# MIK32 register map
Vendor: Mikron JSC; Series: MIK32; File version: 1.0
Registers are 32-bit, read-write, reset 0x0 unless marked. A register's access mark holds for its fields unless they carry their own. Offsets are from the block's base; [hi:lo] are bit positions.

## DAC0 — Управление ЦАП
Base 0x00085000
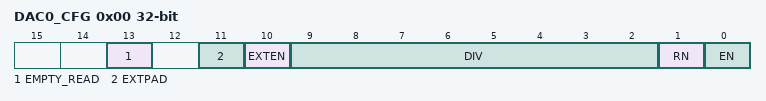
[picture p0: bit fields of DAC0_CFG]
0x00 DAC0_CFG — Регистр настройки ЦАП0
  [13] EMPTY_READ ro — Признак заполненности регистра DAC_VALUE
    0=Full (Значение, хранящееся в DAC_VALUE было сдвинуто в ЦАП, возможна запись следующего значения); 1=Empty (В регистре DAC_Value находится необработанное значение. Автоматически сбрасывается при записи в DAC_Value)
  [11] EXTPAD — Выбор источника внешнего опорного напряжения
    0=Calibrated_voltage_reference (Настраиваемый ИОН); 1=REF_DAC_PIN (Внешний вывод REF_ADC_DAC (PORT1_11))
  [10] EXTEN — Выбор источника опорного напряжения
    0=Internal (Встроенный); 1=External (Внешний)
  [9:2] DIV — Значение делителя тактового сигнала. Частота определяется как FЦАП=FIN/(DIV+1)
  [1] RN — Управление сбросом ЦАП, активный уровень «0»
  [0] EN — Управление питанием ЦАП
    0=Disable (Выключен); 1=Enable (Включен)
0x04 DAC0_VALUE — Входные данные для ЦАП0
  [11:0] VALUE — Входные данные для прерывания

## DAC1 — Управление ЦАП
Base 0x00085008
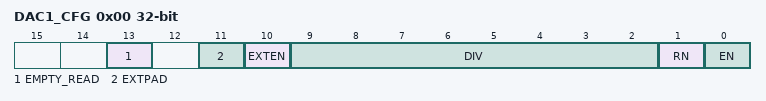
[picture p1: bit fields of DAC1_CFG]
0x00 DAC1_CFG — Регистр настройки ЦАП1
  [13] EMPTY_READ ro — Признак заполненности регистра DAC_VALUE
    0=Full (Значение, хранящееся в DAC_VALUE было сдвинуто в ЦАП, возможна запись следующего значения); 1=Empty (В регистре DAC_Value находится необработанное значение. Автоматически сбрасывается при записи в DAC_Value)
  [11] EXTPAD — Выбор источника внешнего опорного напряжения
    0=Calibrated_voltage_reference (Настраиваемый ИОН); 1=REF_DAC_PIN (Внешний вывод REF_ADC_DAC (PORT1_11))
  [10] EXTEN — Выбор источника опорного напряжения
    0=Internal (Встроенный); 1=External (Внешний)
  [9:2] DIV — Значение делителя тактового сигнала. Частота определяется как FЦАП=FIN/(DIV+1)
  [1] RN — Управление сбросом ЦАП, активный уровень «0»
  [0] EN — Управление питанием ЦАП
    0=Disable (Выключен); 1=Enable (Включен)
0x04 DAC1_VALUE — Входные данные для ЦАП1
  [11:0] VALUE — Входные данные для прерывания

## TSENS — Управление температурным сенсором
Base 0x0008501C
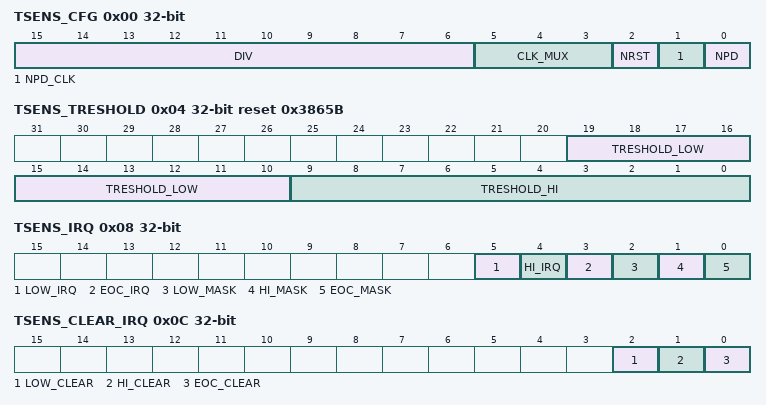
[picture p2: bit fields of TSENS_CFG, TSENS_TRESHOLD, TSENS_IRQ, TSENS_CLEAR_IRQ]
0x00 TSENS_CFG — Регистр настроек
  [15:6] DIV — Значение делителя тактового сигнала. Частота сенсора определяется как Tsens = Fin/(2*(Div + 1))
  [5:3] CLK_MUX — Выбор источника тактирования сенсора (Fin)
    0=Sys_clk (системная частота (sys_clk)); 1=HCLK (Частота шины AHB (hclk)); 2=OSC32M (Частота внешнего осциллятора 32 МГц); 3=HSI32M (Частота HSI32M); 4=OSC32K (Частота внешнего осциллятора 32 кГц); 5=LSI32K (Частота LSI32K)
  [2] NRST — Управление сбросом сенсора, активный уровень «0»
  [1] NPD_CLK — Управление тактированием сенсора
    0=Disable (Тактирование сенсора выключено); 1=Enable (Тактирование сенсора включено)
  [0] NPD — Управление питанием сенсора
    0=Disable (Сенсор выключен); 1=Enable (Сенсор включен)
0x04 TSENS_TRESHOLD reset 0x3865B — Регистр пороговых значений
  [19:10] TRESHOLD_LOW — При значении выхода сенсора менее LOW_THRESHOLD будет формироваться прерывание. Значение по умолчанию соответсвует температуре -40 *C
  [9:0] TRESHOLD_HI — При значении выхода сенсора больше HI_THRESHOLD будет формироваться прерывание. Значение по умолчанию соответсвует температуре +125 *С
0x08 TSENS_IRQ — Регистр прерываний
  [5] LOW_IRQ ro — Статус прерывания события «выход сенсора меньше порогового значения LOW_ THRESHOLD»
  [4] HI_IRQ ro — Статус прерывания события «выход сенсора больше порогового значения HI_THRESHOLD»
  [3] EOC_IRQ ro — Статус прерывания по окончанию преобразования
  [2] LOW_MASK — Маска прерывания события «выход сенсора меньше порогового значения LOW_ THRESHOLD»
  [1] HI_MASK — Маска прерывания события «выход сенсора больше порогового значения HI_THRESHOLD»
  [0] EOC_MASK — Маска прерывания по окончанию преобразования
0x0C TSENS_CLEAR_IRQ wo write-1-clears — Регистр сброса прерываний
  [2] LOW_CLEAR write-1-clears — Сброс прерывания события «выход сенсора меньше порогового значения LOW_ THRESHOLD»
  [1] HI_CLEAR write-1-clears — Сброс прерывания события «выход сенсора больше порогового значения HI_THRESHOLD»
  [0] EOC_CLEAR write-1-clears — Сброс прерывания по окончанию преобразования
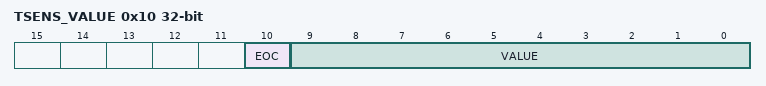
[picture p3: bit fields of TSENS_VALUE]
0x10 TSENS_VALUE ro — Регистр данных
  [10] EOC — Текущее значение выхода окончания преобразования
  [9:0] VALUE — Последнее измереннное значение сенсором
0x14 TSENS_SINGLE wo — Регистр запуска однократного измерения
  [0] SINGLE — Запуск одного измерения
0x18 TSENS_CONTINUOUS wo — Регистр запуска непрерывного измерения
  [0] CONTINUOUS — Запуск / остановка непрерывного измерения температуры

## REFV_CONFIG — Управление калибруемыми источниками напряжения и тока
Base 0x00085038
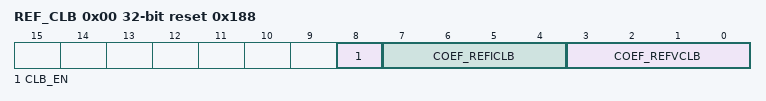
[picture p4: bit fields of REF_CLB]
0x00 REF_CLB reset 0x188 — Управление калибруемыми источниками тока и напряжения
  [8] CLB_EN — Разрешение работы калибруемых источников
    0=Disable (Включить); 1=Enable (Выключить)
  [7:4] COEF_REFICLB — Коэфициент настройки опорного источника тока
  [3:0] COEF_REFVCLB — Коэфициент настройки опорного источника напряжения

## ADC — Управление АЦП
Base 0x0008503C
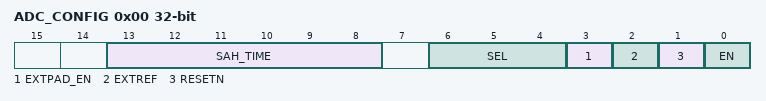
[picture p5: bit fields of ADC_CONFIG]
0x00 ADC_CONFIG — Регистр настройки АЦП
  [13:8] SAH_TIME — Время выборки очередного отсчёта в тактах АЦП
  [6:4] SEL — Выбор канала АЦП
  [3] EXTPAD_EN — Выбор источника внешнего опорного напряжения
    0=Calibrated_voltage_reference (Настраиваемый ИОН); 1=REF_DAC_PIN (Внешний вывод REF_ADC_DAC (PORT1_11))
  [2] EXTREF — Выбор источника опорного напряжения
    0=Internal (Встроенный); 1=External (Внешний)
  [1] RESETN — Управление сбросом АЦП, активный уровень «0»
  [0] EN — Управление питанием АЦП
    0=Disable (Выключен); 1=Enable (Включен)
0x04 ADC_CONTINUOUS — Управление непрерывным измерением
  [0] CONTINUOUS — Запуск / остановка непрерывного измерения
0x08 ADC_SINGLE wo — Управление однократным измерением
  [0] SINGLE — Запуск однократного измерения
0x0C ADC_VALID ro — Регистр статуса
  [0] VALID — Признак наличия актуальных данных
0x10 ADC_VALUE ro — Регистр данных
  [11:0] VALUE — Результат преобразования

## SCR1_TIMER — Регистры 64-разрядного таймера ядра SCR1
Base 0x00490000
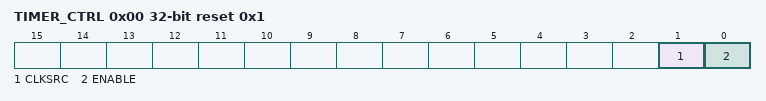
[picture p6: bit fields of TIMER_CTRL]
0x00 TIMER_CTRL reset 0x1 — Регистр конфигурации
  [1] CLKSRC — Источник тактирования
    0=CPU_AHB_CLK ((до 32 МГц) AHB_CLK ядра процессора); 1=CPU_RTC_CLK ((32768 Гц) OSC32K или LSI32K, выбирается в PM.CPU_RTC_CLK_MUX)
  [0] ENABLE — Включение таймера
    0=Diasable (Таймер выключен); 1=Enable (Таймер включён)
0x04 TIMER_DIV — Делитель частоты. Счёт идёт каждые DIV+1 такта
  [9:0] DIV — 10-разрядный регистр делителя частоты
0x08 MTIME — Счётчик таймера, младшее слово
0x0C MTIMEH — Счётчик таймера, старшее слово
0x10 MTIMECMP — Регистр сравнения, младшее слово
0x14 MTIMECMPH — Регистр сравнения, старшее слово
